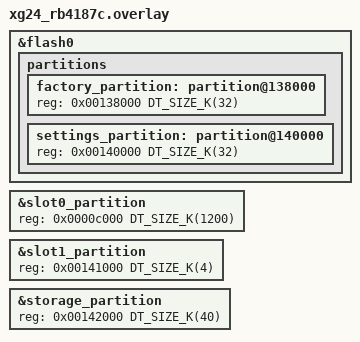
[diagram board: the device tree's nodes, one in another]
/*
 *    Copyright (c) 2025 Project CHIP Authors
 *    All rights reserved.
 *
 *    Licensed under the Apache License, Version 2.0 (the "License");
 *    you may not use this file except in compliance with the License.
 *    You may obtain a copy of the License at
 *
 *        http://www.apache.org/licenses/LICENSE-2.0
 *
 *    Unless required by applicable law or agreed to in writing, software
 *    distributed under the License is distributed on an "AS IS" BASIS
 *    WITHOUT WARRANTIES OR CONDITIONS OF ANY KIND, either express or implied.
 *    See the License for the specific language governing permissions and
 *    limitations under the License.
 */



&flash0 {
	partitions {
            factory_partition: partition@138000 {
                    reg = <0x00138000 DT_SIZE_K(32)>;
            };

            settings_partition: partition@140000 {
                    reg = <0x00140000 DT_SIZE_K(32)>;
            };
	};
};

&slot0_partition {
    reg = <0x0000c000 DT_SIZE_K(1200)>;
};

&slot1_partition {
    reg = <0x00141000 DT_SIZE_K(4)>;
};

/* Set 32 kB of storage at the end of the 1536 kB of flash */
&storage_partition {
    reg = <0x00142000 DT_SIZE_K(40)>;
};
